# PY32T020xx register map
Vendor: Puya; Series: PY32L0; File version: 1.0.0
CPU: CM0+ r0p1, little endian, no MPU, no FPU, 4 interrupt priority bits
Registers are 32-bit, read-write, reset 0x0 unless marked. A register's access mark holds for its fields unless they carry their own. Offsets are from the block's base; [hi:lo] are bit positions.

## IWDG — Independent watchdog
Base 0x40003000
0x00 KR wo — Key register (IWDG_KR)
  [15:0] KEY — Key value
0x04 PR — Prescaler register (IWDG_PR)
  [2:0] PR — Prescaler divider
0x08 RLR reset 0xFFF — Reload register (IWDG_RLR)
  [11:0] RL — Watchdog counter reload value
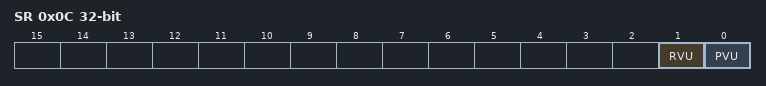
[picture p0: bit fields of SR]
0x0C SR ro — Status register (IWDG_SR)
  [1] RVU — Watchdog counter reload value update
  [0] PVU — Watchdog prescaler value update

## LPTIM1 — Low power timer
Base 0x40007C00
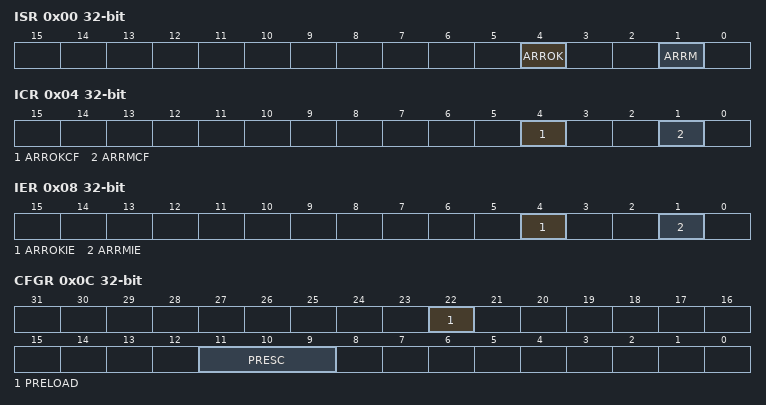
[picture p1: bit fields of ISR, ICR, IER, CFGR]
0x00 ISR ro — Interrupt and Status Register
  [4] ARROK — Autoreload match update OK
  [1] ARRM — Autoreload match
0x04 ICR wo — Interrupt Clear Register
  [4] ARROKCF — Autoreload match update OK Clear Flag
  [1] ARRMCF — Autoreload match Clear Flag
0x08 IER — Interrupt Enable Register
  [4] ARROKIE — Autoreload match update OK Interrupt Enable
  [1] ARRMIE — Autoreload matchInterrupt Enable
0x0C CFGR — Configuration Register
  [22] PRELOAD — Registers update mode
  [11:9] PRESC — Clock prescaler
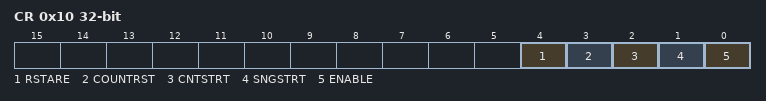
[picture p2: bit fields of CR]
0x10 CR — Control Register
  [4] RSTARE — Reset after read enable
  [3] COUNTRST — Reset counter
  [2] CNTSTRT
  [1] SNGSTRT — LPTIM start in single mode
  [0] ENABLE — LPTIM Enable
0x18 ARR reset 0x1 — Autoreload Register
  [15:0] ARR — Auto reload value
0x1C CNT ro — Counter Register
  [15:0] CNT — Counter value

## PWR — Power control
Base 0x40007000
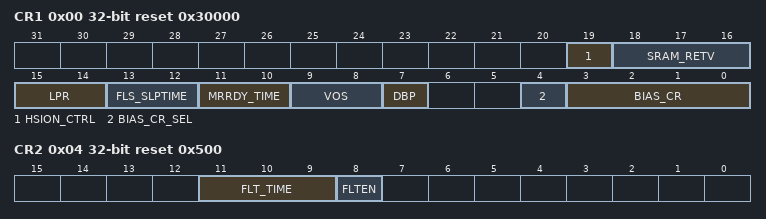
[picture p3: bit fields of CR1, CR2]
0x00 CR1 reset 0x30000 — Power control register 1
  [19] HSION_CTRL — HSI open time control
  [18:16] SRAM_RETV — SRAM retention voltage control
  [15:14] LPR — Low-power run
  [13:12] FLS_SLPTIME — Flash wait time after wakeup from the stop mode
  [11:10] MRRDY_TIME — Time selection wakeup from LP to VR
  [9:8] VOS — Voltage scaling range selection
  [7] DBP — Disable backup domain write protection
  [4] BIAS_CR_SEL — MR Bias current selection
  [3:0] BIAS_CR — MR Bias current
0x04 CR2 reset 0x500 — Power control register 2
  [11:9] FLT_TIME — Digital filter time configuration
  [8] FLTEN — Digital filter enable

## RTC — Real time clock
Base 0x40002800
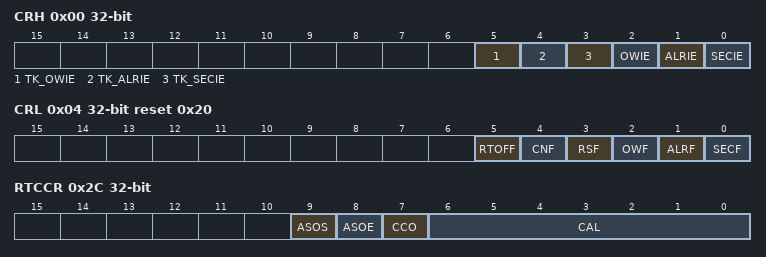
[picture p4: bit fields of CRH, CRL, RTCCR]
0x00 CRH — RTC Control Register High
  [5] TK_OWIE
  [4] TK_ALRIE
  [3] TK_SECIE
  [2] OWIE — Overflow interrupt Enable
  [1] ALRIE — Alarm interrupt Enable
  [0] SECIE — Second interrupt Enable
0x04 CRL reset 0x20 — RTC Control Register Low
  [5] RTOFF ro — RTC operation OFF
  [4] CNF — Configuration Flag
  [3] RSF — Registers Synchronized Flag
  [2] OWF — Overflow Flag
  [1] ALRF — Alarm Flag
  [0] SECF — Second Flag
0x08 PRLH wo — RTC Prescaler Load Register High
  [3:0] PRLH
0x0C PRLL wo reset 0x8000 — RTC Prescaler Load Register Low
  [15:0] PRLL — RTC Prescaler Divider Register Low
0x10 DIVH ro — RTC Prescaler Divider Register High
  [3:0] DIVH — RTC prescaler divider register high
0x14 DIVL ro reset 0x8000 — RTC Prescaler Divider Register Low
  [15:0] DIVL — RTC prescaler divider register Low
0x18 CNTH — RTC Counter Register High
  [15:0] CNTH — RTC counter register high
0x1C CNTL — RTC Counter Register Low
  [15:0] CNTL — RTC counter register Low
0x20 ALRH wo reset 0xFFFF — RTC Alarm Register High
  [15:0] ALRH — RTC alarm register high
0x24 ALRL wo reset 0xFFFF — RTC Alarm Register Low
  [15:0] ALRL — RTC alarm register low
0x2C RTCCR — RTC clock calibration
  [9] ASOS — Alarm or second output selection
  [8] ASOE — Alarm or second output enable
  [7] CCO — Calibration clock output
  [6:0] CAL — Calibration value

## SPI1 — Serial peripheral interface
Base 0x40013000
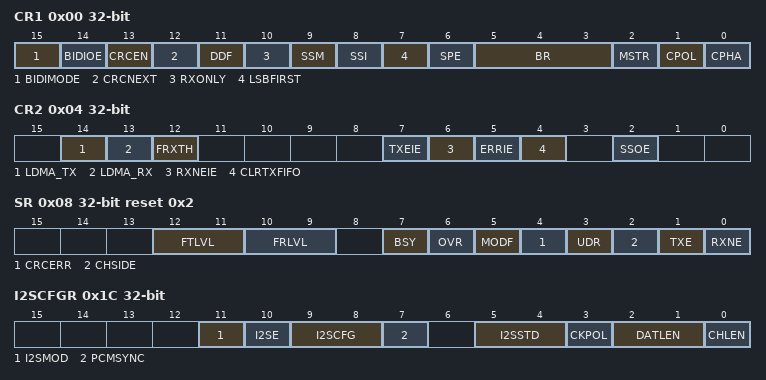
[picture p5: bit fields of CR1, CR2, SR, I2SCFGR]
0x00 CR1
  [15] BIDIMODE, [14] BIDIOE, [13] CRCEN, [12] CRCNEXT, [11] DDF, [10] RXONLY, [9] SSM, [8] SSI, [7] LSBFIRST, [6] SPE, [5:3] BR, [2] MSTR, [1] CPOL, [0] CPHA
0x04 CR2
  [14] LDMA_TX, [13] LDMA_RX, [12] FRXTH, [7] TXEIE, [6] RXNEIE, [5] ERRIE, [4] CLRTXFIFO, [2] SSOE
0x08 SR reset 0x2
  [12:11] FTLVL ro, [10:9] FRLVL ro, [7] BSY ro, [6] OVR ro, [5] MODF ro, [4] CRCERR, [3] UDR ro, [2] CHSIDE ro, [1] TXE ro, [0] RXNE ro
0x0C DR
  [15:0] DR
0x10 CRCPR reset 0x7
  [15:0] CRCPOLY
0x14 RXCRCR ro
  [15:0] RXCRC
0x18 TXCRCR ro
  [15:0] TXCRC
0x1C I2SCFGR
  [11] I2SMOD, [10] I2SE, [9:8] I2SCFG, [7] PCMSYNC, [5:4] I2SSTD, [3] CKPOL, [2:1] DATLEN, [0] CHLEN
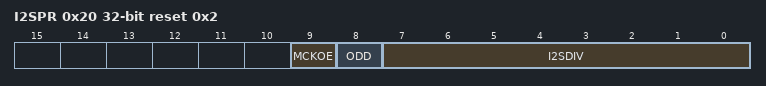
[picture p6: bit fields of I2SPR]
0x20 I2SPR reset 0x2
  [9] MCKOE, [8] ODD, [7:0] I2SDIV
